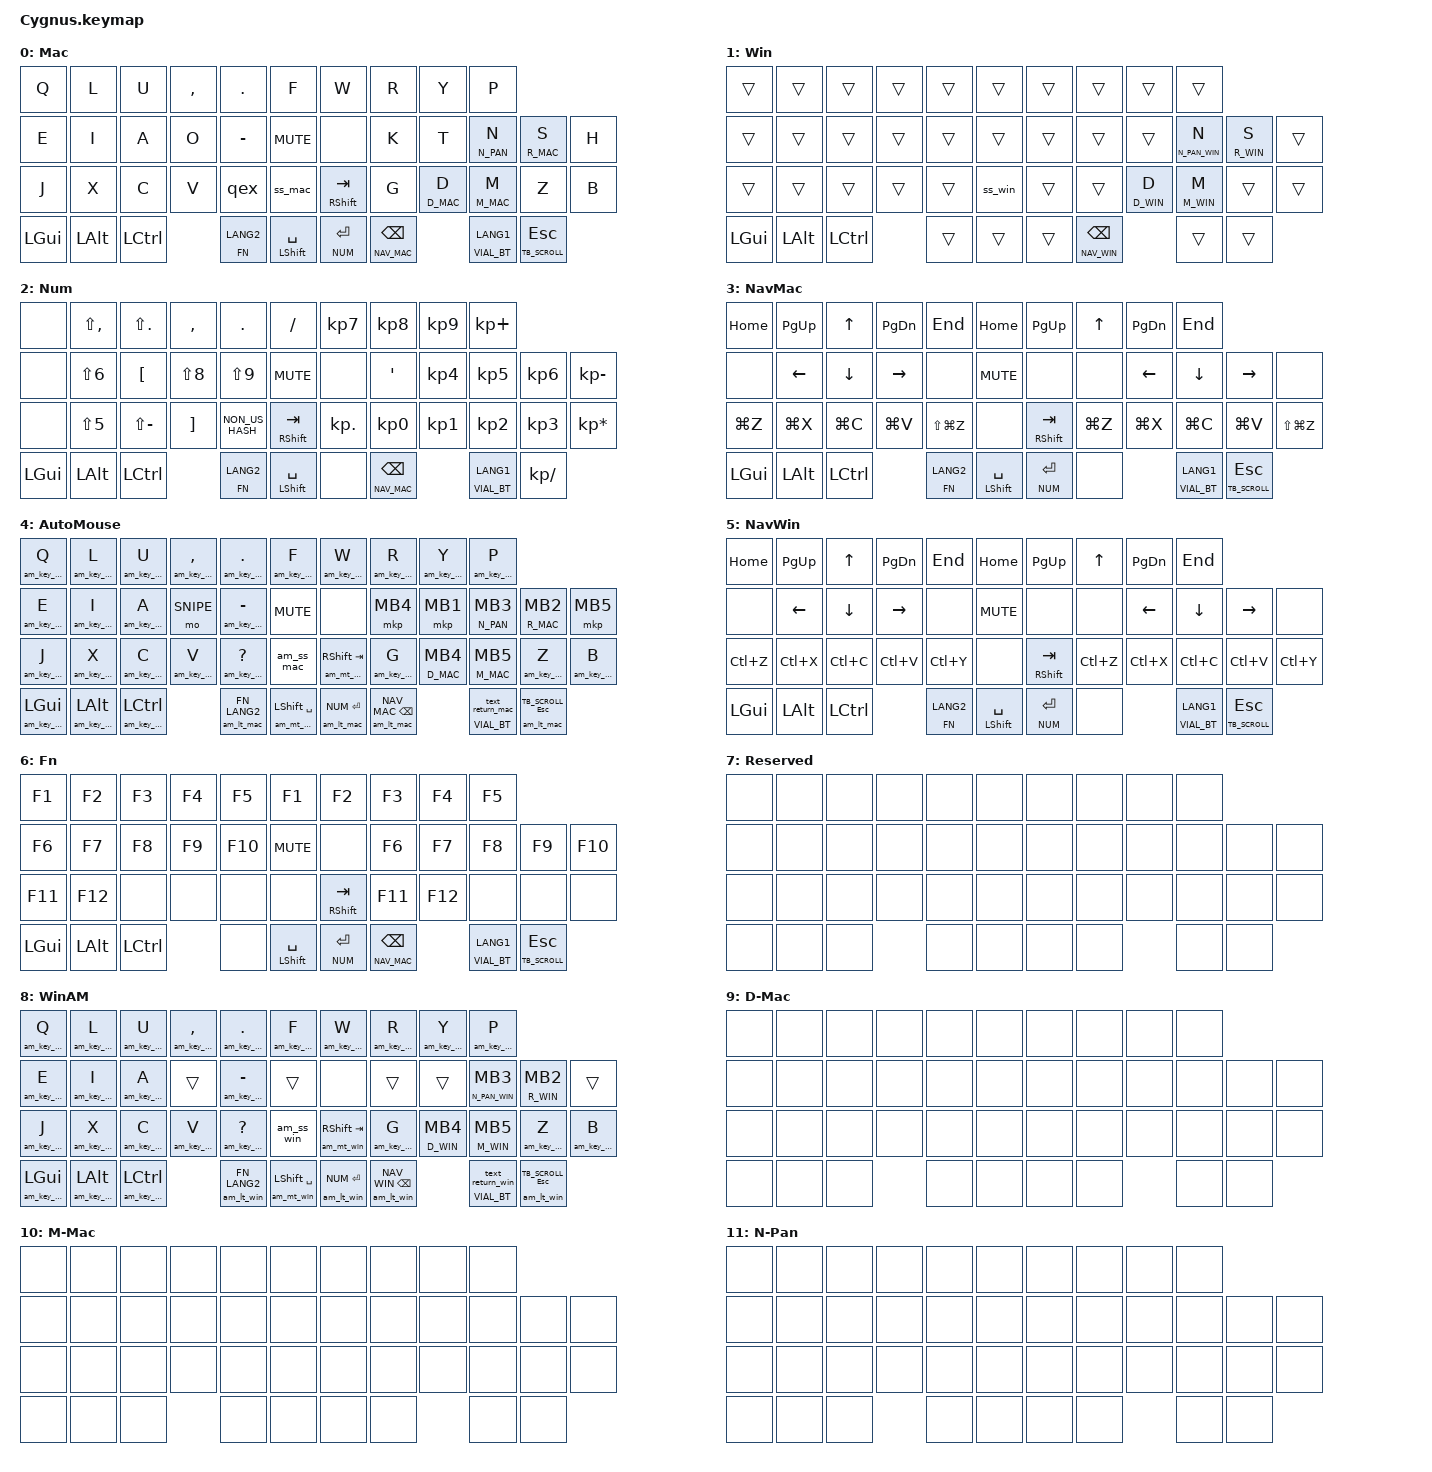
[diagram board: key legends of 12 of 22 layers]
// Cygnus-S keymap
// v10: Vial-aligned daily layout + reliable Kana/BT hold-tap.
// - BT0/BT1: Mac host profile.
// - BT2: Windows host profile via overlay layer.
// - Encoder is volume on Base/Num/AutoMouse, horizontal scroll on Nav, and brightness on Fn/BT.
// - N-hold pan is host-aware so Mac can reverse vertical scroll without changing Windows.
// - Trackball keeps AutoMouse on Layer 4.
// - AutoMouse is mouse/gesture mode; unassigned keys fall through as base text and return to text.
// - N/right-click/D/M positions use hold-tap for gesture families on Base and AutoMouse.
// - Hold Esc for trackball scroll; vertical trackball scroll is inverted in Cygnus_R.conf.
// - Kana always taps LANG1 when released alone; hold past 220 ms and press another key for BT.

// Match the original Cygnus-S encoder scroll strength; ZMK's default is too small on macOS.
#define ZMK_POINTING_DEFAULT_SCRL_VAL 120

#include <behaviors.dtsi>
#include <dt-bindings/zmk/bt.h>
#include <dt-bindings/zmk/keys.h>
#include <dt-bindings/zmk/pointing.h>

#define BASE 0
#define WIN 1
#define NUM 2
#define NAV_MAC 3
#define AMOUSE 4
#define NAV_WIN 5
#define FN 6
#define RESERVED_SYS 7
#define WIN_AMOUSE 8
#define D_MAC 9
#define M_MAC 10
#define N_PAN 11
#define D_WIN 12
#define M_WIN 13
#define WIN_NUM 14
#define WIN_FN 15
#define R_MAC 16
#define R_WIN 17
#define SNIPE 18
#define N_PAN_WIN 19
#define VIAL_BT 20
#define TB_SCROLL 21

&lt {
    tapping-term-ms = <200>;
    quick-tap-ms = <300>;
    flavor = "balanced";
};

&mt {
    flavor = "balanced";
    tapping-term-ms = <200>;
    quick-tap-ms = <0>;
};

/ {
    conditional_layers {
        compatible = "zmk,conditional-layers";

        win_automouse {
            if-layers = <WIN AMOUSE>;
            then-layer = <WIN_AMOUSE>;
        };

        win_num {
            if-layers = <WIN NUM>;
            then-layer = <WIN_NUM>;
        };

        win_fn {
            if-layers = <WIN FN>;
            then-layer = <WIN_FN>;
        };
    };

    behaviors {
        rot_scroll: encoder_scroll {
            compatible = "zmk,behavior-sensor-rotate-var";
            label = "ROT_SCROLL";
            #sensor-binding-cells = <2>;
            bindings = <&msc>, <&msc>;
            // Hold scroll long enough for the mouse-scroll behavior to emit reliably.
            tap-ms = <60>;
        };

        mg: mouse_gesture {
            compatible = "zmk,behavior-hold-tap";
            label = "MOUSE_GESTURE";
            #binding-cells = <2>;
            flavor = "balanced";
            tapping-term-ms = <300>;
            quick-tap-ms = <0>;
            hold-while-undecided;
            bindings = <&mo>, <&mkp>;
        };

        kg: key_gesture {
            compatible = "zmk,behavior-hold-tap";
            label = "KEY_GESTURE";
            #binding-cells = <2>;
            flavor = "tap-preferred";
            tapping-term-ms = <300>;
            quick-tap-ms = <0>;
            hold-while-undecided;
            bindings = <&mo>, <&kp>;
        };

        qex: question_exclaim {
            compatible = "zmk,behavior-mod-morph";
            label = "QUESTION_EXCLAIM";
            #binding-cells = <0>;
            bindings = <&kp QMARK>, <&kp EXCL>;
            mods = <(MOD_LSFT|MOD_RSFT)>;
        };

        kana_bt: kana_bluetooth_layer_tap {
            compatible = "zmk,behavior-hold-tap";
            label = "KANA_BLUETOOTH_LAYER_TAP";
            #binding-cells = <2>;
            flavor = "tap-preferred";
            tapping-term-ms = <220>;
            quick-tap-ms = <0>;
            retro-tap;
            bindings = <&mo>, <&kp>;
        };

        am_kana_bt_mac: automouse_kana_bluetooth_mac {
            compatible = "zmk,behavior-hold-tap";
            label = "AUTOMOUSE_KANA_BLUETOOTH_MAC";
            #binding-cells = <2>;
            flavor = "tap-preferred";
            tapping-term-ms = <220>;
            quick-tap-ms = <0>;
            retro-tap;
            bindings = <&mo>, <&text_return_mac>;
        };

        am_kana_bt_win: automouse_kana_bluetooth_win {
            compatible = "zmk,behavior-hold-tap";
            label = "AUTOMOUSE_KANA_BLUETOOTH_WIN";
            #binding-cells = <2>;
            flavor = "tap-preferred";
            tapping-term-ms = <220>;
            quick-tap-ms = <0>;
            retro-tap;
            bindings = <&mo>, <&text_return_win>;
        };
    };

    macros {
        ss_mac: screenshot_mac {
            compatible = "zmk,behavior-macro";
            #binding-cells = <0>;
            wait-ms = <0>;
            tap-ms = <20>;
            bindings = <&kp LC(LS(LG(N4)))>;
        };

        ss_win: screenshot_win {
            compatible = "zmk,behavior-macro";
            #binding-cells = <0>;
            wait-ms = <0>;
            tap-ms = <20>;
            bindings = <&kp LS(LG(S))>;
        };

        am_ss_mac: automouse_screenshot_mac {
            compatible = "zmk,behavior-macro";
            #binding-cells = <0>;
            wait-ms = <0>;
            tap-ms = <20>;
            bindings = <&to BASE &kp LC(LS(LG(N4)))>;
        };

        am_ss_win: automouse_screenshot_win {
            compatible = "zmk,behavior-macro";
            #binding-cells = <0>;
            wait-ms = <0>;
            tap-ms = <20>;
            bindings = <&to WIN &kp LS(LG(S))>;
        };

        text_return_mac: text_return_mac {
            compatible = "zmk,behavior-macro";
            #binding-cells = <0>;
            wait-ms = <0>;
            tap-ms = <20>;
            bindings = <&kp LANG1 &to BASE>;
        };

        text_return_win: text_return_win {
            compatible = "zmk,behavior-macro";
            #binding-cells = <0>;
            wait-ms = <0>;
            tap-ms = <20>;
            bindings = <&kp LANG1 &to WIN>;
        };

        text_return_mac_en: text_return_mac_en {
            compatible = "zmk,behavior-macro";
            #binding-cells = <0>;
            wait-ms = <0>;
            tap-ms = <20>;
            bindings = <&kp LANG2 &to BASE>;
        };

        text_return_win_en: text_return_win_en {
            compatible = "zmk,behavior-macro";
            #binding-cells = <0>;
            wait-ms = <0>;
            tap-ms = <20>;
            bindings = <&kp LANG2 &to WIN>;
        };

        am_key_mac: automouse_key_mac {
            compatible = "zmk,behavior-macro-one-param";
            #binding-cells = <1>;
            wait-ms = <0>;
            tap-ms = <20>;
            bindings =
                <&to BASE>,
                <&macro_param_1to1>,
                <&macro_press &kp MACRO_PLACEHOLDER>,
                <&macro_pause_for_release>,
                <&macro_param_1to1>,
                <&macro_release &kp MACRO_PLACEHOLDER>;
        };

        am_key_win: automouse_key_win {
            compatible = "zmk,behavior-macro-one-param";
            #binding-cells = <1>;
            wait-ms = <0>;
            tap-ms = <20>;
            bindings =
                <&to WIN>,
                <&macro_param_1to1>,
                <&macro_press &kp MACRO_PLACEHOLDER>,
                <&macro_pause_for_release>,
                <&macro_param_1to1>,
                <&macro_release &kp MACRO_PLACEHOLDER>;
        };

        am_lt_mac: automouse_layer_tap_mac {
            compatible = "zmk,behavior-macro-two-param";
            #binding-cells = <2>;
            wait-ms = <0>;
            tap-ms = <20>;
            bindings =
                <&to BASE>,
                <&macro_param_1to1>,
                <&macro_param_2to2>,
                <&macro_press &lt MACRO_PLACEHOLDER MACRO_PLACEHOLDER>,
                <&macro_pause_for_release>,
                <&macro_param_1to1>,
                <&macro_param_2to2>,
                <&macro_release &lt MACRO_PLACEHOLDER MACRO_PLACEHOLDER>;
        };

        am_lt_win: automouse_layer_tap_win {
            compatible = "zmk,behavior-macro-two-param";
            #binding-cells = <2>;
            wait-ms = <0>;
            tap-ms = <20>;
            bindings =
                <&to WIN>,
                <&macro_param_1to1>,
                <&macro_param_2to2>,
                <&macro_press &lt MACRO_PLACEHOLDER MACRO_PLACEHOLDER>,
                <&macro_pause_for_release>,
                <&macro_param_1to1>,
                <&macro_param_2to2>,
                <&macro_release &lt MACRO_PLACEHOLDER MACRO_PLACEHOLDER>;
        };

        am_mt_mac: automouse_mod_tap_mac {
            compatible = "zmk,behavior-macro-two-param";
            #binding-cells = <2>;
            wait-ms = <0>;
            tap-ms = <20>;
            bindings =
                <&to BASE>,
                <&macro_param_1to1>,
                <&macro_param_2to2>,
                <&macro_press &mt MACRO_PLACEHOLDER MACRO_PLACEHOLDER>,
                <&macro_pause_for_release>,
                <&macro_param_1to1>,
                <&macro_param_2to2>,
                <&macro_release &mt MACRO_PLACEHOLDER MACRO_PLACEHOLDER>;
        };

        am_mt_win: automouse_mod_tap_win {
            compatible = "zmk,behavior-macro-two-param";
            #binding-cells = <2>;
            wait-ms = <0>;
            tap-ms = <20>;
            bindings =
                <&to WIN>,
                <&macro_param_1to1>,
                <&macro_param_2to2>,
                <&macro_press &mt MACRO_PLACEHOLDER MACRO_PLACEHOLDER>,
                <&macro_pause_for_release>,
                <&macro_param_1to1>,
                <&macro_param_2to2>,
                <&macro_release &mt MACRO_PLACEHOLDER MACRO_PLACEHOLDER>;
        };

        bt0_mac: bt0_mac {
            compatible = "zmk,behavior-macro";
            #binding-cells = <0>;
            wait-ms = <0>;
            tap-ms = <20>;
            bindings = <&bt BT_SEL 0 &to BASE>;
        };

        bt1_mac: bt1_mac {
            compatible = "zmk,behavior-macro";
            #binding-cells = <0>;
            wait-ms = <0>;
            tap-ms = <20>;
            bindings = <&bt BT_SEL 1 &to BASE>;
        };

        bt2_win: bt2_win {
            compatible = "zmk,behavior-macro";
            #binding-cells = <0>;
            wait-ms = <0>;
            tap-ms = <20>;
            bindings = <&bt BT_SEL 2 &to WIN>;
        };

        bt3_win: bt3_win {
            compatible = "zmk,behavior-macro";
            #binding-cells = <0>;
            wait-ms = <0>;
            tap-ms = <20>;
            bindings = <&bt BT_SEL 3 &to WIN>;
        };

        bt4_win: bt4_win {
            compatible = "zmk,behavior-macro";
            #binding-cells = <0>;
            wait-ms = <0>;
            tap-ms = <20>;
            bindings = <&bt BT_SEL 4 &to WIN>;
        };
    };

    keymap {
        compatible = "zmk,keymap";

        default_layer { // Layer 0: Mac/Common Base
            display-name = "Mac";
            sensor-bindings = <&inc_dec_kp C_VOL_UP C_VOL_DN &inc_dec_kp C_VOL_UP C_VOL_DN>;
            bindings = <
                    &kp Q  &kp L  &kp U  &kp COMMA  &kp DOT  &kp F  &kp W  &kp R  &kp Y  &kp P
                    &kp E  &kp I  &kp A  &kp O  &kp MINUS  &kp C_MUTE  &none  &kp K  &kp T  &kg N_PAN N  &kg R_MAC S  &kp H
                    &kp J  &kp X  &kp C  &kp V  &qex  &ss_mac  &mt RSHIFT TAB  &kp G  &kg D_MAC D  &kg M_MAC M  &kp Z  &kp B
                    &kp LGUI  &kp LALT  &kp LCTRL  &lt FN LANG2  &mt LSHIFT SPACE  &lt NUM ENTER  &lt NAV_MAC BSPC  &kana_bt VIAL_BT LANG1  &lt TB_SCROLL ESCAPE
            >;
        };

        windows_overlay_layer { // Layer 1: Windows overlay
            display-name = "Win";
            sensor-bindings = <&inc_dec_kp C_VOL_UP C_VOL_DN &inc_dec_kp C_VOL_UP C_VOL_DN>;
            bindings = <
                    &trans  &trans  &trans  &trans  &trans  &trans  &trans  &trans  &trans  &trans
                    &trans  &trans  &trans  &trans  &trans  &trans  &trans  &trans  &trans  &kg N_PAN_WIN N  &kg R_WIN S  &trans
                    &trans  &trans  &trans  &trans  &trans  &ss_win  &trans  &trans  &kg D_WIN D  &kg M_WIN M  &trans  &trans
                    &kp LGUI  &kp LALT  &kp LCTRL  &trans  &trans  &trans  &lt NAV_WIN BSPC  &trans  &trans
            >;
        };

        num_layer { // Layer 2: Num/Sym
            display-name = "Num";
            sensor-bindings = <&inc_dec_kp C_VOL_UP C_VOL_DN &inc_dec_kp C_VOL_UP C_VOL_DN>;
            bindings = <
                    &none  &kp LS(COMMA)  &kp LS(DOT)  &kp COMMA  &kp DOT  &kp SLASH  &kp KP_NUMBER_7  &kp KP_NUMBER_8  &kp KP_NUMBER_9  &kp KP_PLUS
                    &none  &kp LS(N6)  &kp LBKT  &kp LS(N8)  &kp LS(N9)  &kp C_MUTE  &none  &kp SQT  &kp KP_NUMBER_4  &kp KP_NUMBER_5  &kp KP_NUMBER_6  &kp KP_MINUS
                    &none  &kp LS(N5)  &kp LS(MINUS)  &kp RBKT  &kp NON_US_HASH  &mt RSHIFT TAB  &kp KP_DOT  &kp KP_NUMBER_0  &kp KP_NUMBER_1  &kp KP_NUMBER_2  &kp KP_NUMBER_3  &kp KP_MULTIPLY
                    &kp LGUI  &kp LALT  &kp LCTRL  &lt FN LANG2  &mt LSHIFT SPACE  &none  &lt NAV_MAC BSPC  &kana_bt VIAL_BT LANG1  &kp KP_DIVIDE
            >;
        };

        nav_mac_layer { // Layer 3: Nav/Edit Mac
            display-name = "NavMac";
            sensor-bindings = <&rot_scroll SCRL_LEFT SCRL_RIGHT &rot_scroll SCRL_LEFT SCRL_RIGHT>;
            bindings = <
                    &kp HOME  &kp PG_UP  &kp UP_ARROW  &kp PG_DN  &kp END  &kp HOME  &kp PG_UP  &kp UP_ARROW  &kp PG_DN  &kp END
                    &none  &kp LEFT_ARROW  &kp DOWN_ARROW  &kp RIGHT_ARROW  &none  &kp C_MUTE  &none  &none  &kp LEFT_ARROW  &kp DOWN_ARROW  &kp RIGHT_ARROW  &none
                    &kp LG(Z)  &kp LG(X)  &kp LG(C)  &kp LG(V)  &kp LS(LG(Z))  &none  &mt RSHIFT TAB  &kp LG(Z)  &kp LG(X)  &kp LG(C)  &kp LG(V)  &kp LS(LG(Z))
                    &kp LGUI  &kp LALT  &kp LCTRL  &lt FN LANG2  &mt LSHIFT SPACE  &lt NUM ENTER  &none  &kana_bt VIAL_BT LANG1  &lt TB_SCROLL ESCAPE
            >;
        };

        automouse_layer { // Layer 4: AutoMouse
            display-name = "AutoMouse";
            sensor-bindings = <&inc_dec_kp C_VOL_UP C_VOL_DN &inc_dec_kp C_VOL_UP C_VOL_DN>;
            bindings = <
                    &am_key_mac Q  &am_key_mac L  &am_key_mac U  &am_key_mac COMMA  &am_key_mac DOT  &am_key_mac F  &am_key_mac W  &am_key_mac R  &am_key_mac Y  &am_key_mac P
                    &am_key_mac E  &am_key_mac I  &am_key_mac A  &mo SNIPE  &am_key_mac MINUS  &kp C_MUTE  &none  &mkp MB4  &mkp MB1  &mg N_PAN MB3  &mg R_MAC MB2  &mkp MB5
                    &am_key_mac J  &am_key_mac X  &am_key_mac C  &am_key_mac V  &am_key_mac QMARK  &am_ss_mac  &am_mt_mac RSHIFT TAB  &am_key_mac G  &mg D_MAC MB4  &mg M_MAC MB5  &am_key_mac Z  &am_key_mac B
                    &am_key_mac LGUI  &am_key_mac LALT  &am_key_mac LCTRL  &am_lt_mac FN LANG2  &am_mt_mac LSHIFT SPACE  &am_lt_mac NUM ENTER  &am_lt_mac NAV_MAC BSPC  &am_kana_bt_mac VIAL_BT 0  &am_lt_mac TB_SCROLL ESCAPE
            >;
        };

        nav_win_layer { // Layer 5: Nav/Edit Windows
            display-name = "NavWin";
            sensor-bindings = <&rot_scroll SCRL_LEFT SCRL_RIGHT &rot_scroll SCRL_LEFT SCRL_RIGHT>;
            bindings = <
                    &kp HOME  &kp PG_UP  &kp UP_ARROW  &kp PG_DN  &kp END  &kp HOME  &kp PG_UP  &kp UP_ARROW  &kp PG_DN  &kp END
                    &none  &kp LEFT_ARROW  &kp DOWN_ARROW  &kp RIGHT_ARROW  &none  &kp C_MUTE  &none  &none  &kp LEFT_ARROW  &kp DOWN_ARROW  &kp RIGHT_ARROW  &none
                    &kp LC(Z)  &kp LC(X)  &kp LC(C)  &kp LC(V)  &kp LC(Y)  &none  &mt RSHIFT TAB  &kp LC(Z)  &kp LC(X)  &kp LC(C)  &kp LC(V)  &kp LC(Y)
                    &kp LGUI  &kp LALT  &kp LCTRL  &lt FN LANG2  &mt LSHIFT SPACE  &lt NUM ENTER  &none  &kana_bt VIAL_BT LANG1  &lt TB_SCROLL ESCAPE
            >;
        };

        function_layer { // Layer 6: Fn
            display-name = "Fn";
            sensor-bindings = <&inc_dec_kp C_BRI_UP C_BRI_DN &inc_dec_kp C_BRI_UP C_BRI_DN>;
            bindings = <
                    &kp F1  &kp F2  &kp F3  &kp F4  &kp F5  &kp F1  &kp F2  &kp F3  &kp F4  &kp F5
                    &kp F6  &kp F7  &kp F8  &kp F9  &kp F10  &kp C_MUTE  &none  &kp F6  &kp F7  &kp F8  &kp F9  &kp F10
                    &kp F11  &kp F12  &none  &none  &none  &none  &mt RSHIFT TAB  &kp F11  &kp F12  &none  &none  &none
                    &kp LGUI  &kp LALT  &kp LCTRL  &none  &mt LSHIFT SPACE  &lt NUM ENTER  &lt NAV_MAC BSPC  &kana_bt VIAL_BT LANG1  &lt TB_SCROLL ESCAPE
            >;
        };

        reserved_system_layer { // Layer 7: kept reserved so later internal layer numbers stay stable
            display-name = "Reserved";
            sensor-bindings = <&inc_dec_kp C_VOL_UP C_VOL_DN &inc_dec_kp C_VOL_UP C_VOL_DN>;
            bindings = <
                    &none  &none  &none  &none  &none  &none  &none  &none  &none  &none
                    &none  &none  &none  &none  &none  &none  &none  &none  &none  &none  &none  &none
                    &none  &none  &none  &none  &none  &none  &none  &none  &none  &none  &none  &none
                    &none  &none  &none  &none  &none  &none  &none  &none  &none
            >;
        };

        win_automouse_override_layer { // Layer 8: Windows AutoMouse override
            display-name = "WinAM";
            sensor-bindings = <&inc_dec_kp C_VOL_UP C_VOL_DN &inc_dec_kp C_VOL_UP C_VOL_DN>;
            bindings = <
                    &am_key_win Q  &am_key_win L  &am_key_win U  &am_key_win COMMA  &am_key_win DOT  &am_key_win F  &am_key_win W  &am_key_win R  &am_key_win Y  &am_key_win P
                    &am_key_win E  &am_key_win I  &am_key_win A  &trans  &am_key_win MINUS  &trans  &none  &trans  &trans  &mg N_PAN_WIN MB3  &mg R_WIN MB2  &trans
                    &am_key_win J  &am_key_win X  &am_key_win C  &am_key_win V  &am_key_win QMARK  &am_ss_win  &am_mt_win RSHIFT TAB  &am_key_win G  &mg D_WIN MB4  &mg M_WIN MB5  &am_key_win Z  &am_key_win B
                    &am_key_win LGUI  &am_key_win LALT  &am_key_win LCTRL  &am_lt_win FN LANG2  &am_mt_win LSHIFT SPACE  &am_lt_win NUM ENTER  &am_lt_win NAV_WIN BSPC  &am_kana_bt_win VIAL_BT 0  &am_lt_win TB_SCROLL ESCAPE
            >;
        };

        d_mac_gesture_layer { // Layer 9: internal D gesture, Mac
            display-name = "D-Mac";
            sensor-bindings = <&rot_scroll SCRL_UP SCRL_DOWN &rot_scroll SCRL_UP SCRL_DOWN>;
            bindings = <
                    &none &none &none &none &none &none &none &none &none &none
                    &none &none &none &none &none &none &none &none &none &none &none &none
                    &none &none &none &none &none &none &none &none &none &none &none &none
                    &none &none &none &none &none &none &none &none &none
            >;
        };

        m_mac_gesture_layer { // Layer 10: internal M gesture, Mac
            display-name = "M-Mac";
            sensor-bindings = <&rot_scroll SCRL_UP SCRL_DOWN &rot_scroll SCRL_UP SCRL_DOWN>;
            bindings = <
                    &none &none &none &none &none &none &none &none &none &none
                    &none &none &none &none &none &none &none &none &none &none &none &none
                    &none &none &none &none &none &none &none &none &none &none &none &none
                    &none &none &none &none &none &none &none &none &none
            >;
        };

        n_pan_layer { // Layer 11: internal N pan, Mac
            display-name = "N-Pan";
            sensor-bindings = <&rot_scroll SCRL_UP SCRL_DOWN &rot_scroll SCRL_UP SCRL_DOWN>;
            bindings = <
                    &none &none &none &none &none &none &none &none &none &none
                    &none &none &none &none &none &none &none &none &none &none &none &none
                    &none &none &none &none &none &none &none &none &none &none &none &none
                    &none &none &none &none &none &none &none &none &none
            >;
        };

        d_win_gesture_layer { // Layer 12: internal D gesture, Windows
            display-name = "D-Win";
            sensor-bindings = <&rot_scroll SCRL_DOWN SCRL_UP &rot_scroll SCRL_DOWN SCRL_UP>;
            bindings = <
                    &none &none &none &none &none &none &none &none &none &none
                    &none &none &none &none &none &none &none &none &none &none &none &none
                    &none &none &none &none &none &none &none &none &none &none &none &none
                    &none &none &none &none &none &none &none &none &none
            >;
        };

        m_win_gesture_layer { // Layer 13: internal M gesture, Windows
            display-name = "M-Win";
            sensor-bindings = <&rot_scroll SCRL_DOWN SCRL_UP &rot_scroll SCRL_DOWN SCRL_UP>;
            bindings = <
                    &none &none &none &none &none &none &none &none &none &none
                    &none &none &none &none &none &none &none &none &none &none &none &none
                    &none &none &none &none &none &none &none &none &none &none &none &none
                    &none &none &none &none &none &none &none &none &none
            >;
        };

        win_num_override_layer { // Layer 14: Windows Num host override
            display-name = "WinNum";
            sensor-bindings = <&inc_dec_kp C_VOL_UP C_VOL_DN &inc_dec_kp C_VOL_UP C_VOL_DN>;
            bindings = <
                    &trans  &trans  &trans  &trans  &trans  &trans  &trans  &trans  &trans  &trans
                    &trans  &trans  &trans  &trans  &trans  &trans  &trans  &trans  &trans  &trans  &trans  &trans
                    &trans  &trans  &trans  &trans  &trans  &trans  &trans  &trans  &trans  &trans  &trans  &trans
                    &kp LGUI  &kp LALT  &kp LCTRL  &trans  &trans  &trans  &lt NAV_WIN BSPC  &trans  &trans
            >;
        };

        win_fn_override_layer { // Layer 15: Windows Fn host override
            display-name = "WinFn";
            sensor-bindings = <&inc_dec_kp C_BRI_UP C_BRI_DN &inc_dec_kp C_BRI_UP C_BRI_DN>;
            bindings = <
                    &trans  &trans  &trans  &trans  &trans  &trans  &trans  &trans  &trans  &trans
                    &trans  &trans  &trans  &trans  &trans  &trans  &trans  &trans  &trans  &trans  &trans  &trans
                    &trans  &trans  &trans  &trans  &trans  &trans  &trans  &trans  &trans  &trans  &trans  &trans
                    &kp LGUI  &kp LALT  &kp LCTRL  &trans  &trans  &trans  &lt NAV_WIN BSPC  &trans  &trans
            >;
        };

        r_mac_gesture_layer { // Layer 16: internal right-click gesture, Mac
            display-name = "R-Mac";
            sensor-bindings = <&rot_scroll SCRL_UP SCRL_DOWN &rot_scroll SCRL_UP SCRL_DOWN>;
            bindings = <
                    &none &none &none &none &none &none &none &none &none &none
                    &none &none &none &none &none &none &none &none &none &none &none &none
                    &none &none &none &none &none &none &none &none &none &none &none &none
                    &none &none &none &none &none &none &none &none &none
            >;
        };

        r_win_gesture_layer { // Layer 17: internal right-click gesture, Windows
            display-name = "R-Win";
            sensor-bindings = <&rot_scroll SCRL_DOWN SCRL_UP &rot_scroll SCRL_DOWN SCRL_UP>;
            bindings = <
                    &none &none &none &none &none &none &none &none &none &none
                    &none &none &none &none &none &none &none &none &none &none &none &none
                    &none &none &none &none &none &none &none &none &none &none &none &none
                    &none &none &none &none &none &none &none &none &none
            >;
        };

        snipe_layer { // Layer 18: internal pointer slow mode
            display-name = "Slow";
            sensor-bindings = <&rot_scroll SCRL_DOWN SCRL_UP &rot_scroll SCRL_DOWN SCRL_UP>;
            bindings = <
                    &trans &trans &trans &trans &trans &trans &trans &trans &trans &trans
                    &trans &trans &trans &trans &trans &trans &trans &trans &trans &trans &trans &trans
                    &trans &trans &trans &trans &trans &trans &trans &trans &trans &trans &trans &trans
                    &trans &trans &trans &trans &trans &trans &trans &trans &trans
            >;
        };

        n_pan_win_layer { // Layer 19: internal N pan, Windows
            display-name = "N-PanWin";
            sensor-bindings = <&rot_scroll SCRL_DOWN SCRL_UP &rot_scroll SCRL_DOWN SCRL_UP>;
            bindings = <
                    &none &none &none &none &none &none &none &none &none &none
                    &none &none &none &none &none &none &none &none &none &none &none &none
                    &none &none &none &none &none &none &none &none &none &none &none &none
                    &none &none &none &none &none &none &none &none &none
            >;
        };

        vial_bluetooth_layer { // Layer 20: hold Kana for Vial-style Bluetooth profiles
            display-name = "Bluetooth";
            sensor-bindings = <&inc_dec_kp C_BRI_UP C_BRI_DN &inc_dec_kp C_BRI_UP C_BRI_DN>;
            bindings = <
                    &none  &none  &none  &none  &bt0_mac  &none  &none  &none  &none  &none
                    &none  &none  &bt BT_CLR  &none  &bt1_mac  &kp C_MUTE  &none  &none  &none  &none  &none  &none
                    &none  &none  &none  &none  &bt2_win  &none  &mt RSHIFT TAB  &none  &none  &none  &none  &none
                    &trans  &trans  &trans  &trans  &trans  &trans  &trans  &trans  &lt TB_SCROLL ESCAPE
            >;
        };

        trackball_scroll_layer { // Layer 21: hold Esc for inverted vertical PMW3610 scroll
            display-name = "TB-Scroll";
            sensor-bindings = <&inc_dec_kp C_VOL_UP C_VOL_DN &inc_dec_kp C_VOL_UP C_VOL_DN>;
            bindings = <
                    &none  &none  &none  &none  &none  &none  &none  &none  &none  &none
                    &none  &none  &none  &none  &none  &kp C_MUTE  &none  &none  &none  &none  &none  &none
                    &none  &none  &none  &none  &none  &none  &mt RSHIFT TAB  &none  &none  &none  &none  &none
                    &trans  &trans  &trans  &trans  &trans  &trans  &trans  &trans  &trans
            >;
        };
    };
};
